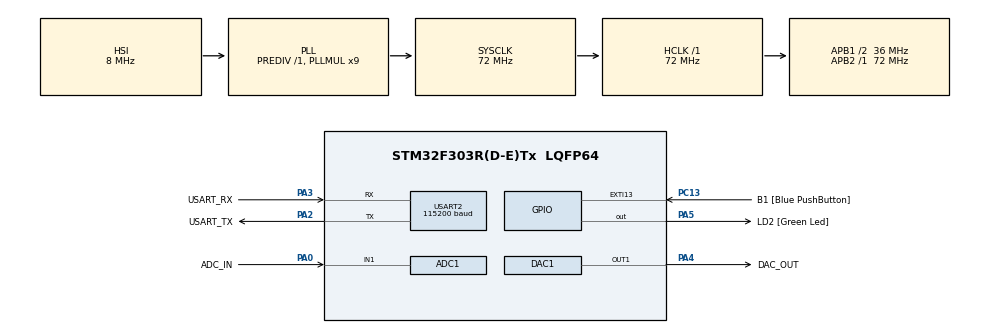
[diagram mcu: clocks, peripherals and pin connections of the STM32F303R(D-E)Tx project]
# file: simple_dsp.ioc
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ADC1.Channel-0\#ChannelRegularConversion=ADC_CHANNEL_1
ADC1.ClockPrescaler=ADC_CLOCK_SYNC_PCLK_DIV2
ADC1.ContinuousConvMode=DISABLE
ADC1.DMAContinuousRequests=ENABLE
ADC1.ExternalTrigConv=ADC_EXTERNALTRIGCONV_T6_TRGO
ADC1.NbrOfConversionFlag=1
ADC1.Offset-0\#ChannelRegularConversion=0
ADC1.OffsetNumber-0\#ChannelRegularConversion=ADC_OFFSET_NONE
ADC1.Rank-0\#ChannelRegularConversion=1
ADC1.SamplingTime-0\#ChannelRegularConversion=ADC_SAMPLETIME_181CYCLES_5
ADC1.master=1
DAC1.DAC_Trigger=DAC_TRIGGER_T6_TRGO
Dma.ADC1.1.Direction=DMA_PERIPH_TO_MEMORY
Dma.ADC1.1.Instance=DMA1_Channel1
Dma.ADC1.1.MemDataAlignment=DMA_MDATAALIGN_HALFWORD
Dma.ADC1.1.MemInc=DMA_MINC_ENABLE
Dma.ADC1.1.Mode=DMA_CIRCULAR
Dma.ADC1.1.PeriphDataAlignment=DMA_PDATAALIGN_HALFWORD
Dma.ADC1.1.PeriphInc=DMA_PINC_DISABLE
Dma.ADC1.1.Priority=DMA_PRIORITY_MEDIUM
Dma.DAC1_CH1.0.Direction=DMA_MEMORY_TO_PERIPH
Dma.DAC1_CH1.0.Instance=DMA1_Channel3
Dma.DAC1_CH1.0.MemDataAlignment=DMA_MDATAALIGN_HALFWORD
Dma.DAC1_CH1.0.MemInc=DMA_MINC_ENABLE
Dma.DAC1_CH1.0.Mode=DMA_CIRCULAR
Dma.DAC1_CH1.0.PeriphDataAlignment=DMA_PDATAALIGN_HALFWORD
Dma.DAC1_CH1.0.PeriphInc=DMA_PINC_DISABLE
Dma.DAC1_CH1.0.Priority=DMA_PRIORITY_MEDIUM
Dma.Request0=DAC1_CH1
Dma.Request1=ADC1
Dma.Request2=USART2_TX
Dma.USART2_TX.2.Direction=DMA_MEMORY_TO_PERIPH
Dma.USART2_TX.2.Instance=DMA1_Channel7
Dma.USART2_TX.2.MemDataAlignment=DMA_MDATAALIGN_BYTE
Dma.USART2_TX.2.MemInc=DMA_MINC_ENABLE
Dma.USART2_TX.2.Mode=DMA_NORMAL
Dma.USART2_TX.2.PeriphDataAlignment=DMA_PDATAALIGN_BYTE
Dma.USART2_TX.2.PeriphInc=DMA_PINC_DISABLE
Dma.USART2_TX.2.Priority=DMA_PRIORITY_LOW
Mcu.Family=STM32F3
Mcu.Name=STM32F303R(D-E)Tx
Mcu.Package=LQFP64
NVIC.DMA1_Channel1_IRQn=true\:0\:0\:false\:false\:false\:false\:false
NVIC.DMA1_Channel3_IRQn=true\:0\:0\:false\:false\:false\:false\:false
NVIC.DMA1_Channel7_IRQn=true\:0\:0\:false\:false\:true\:false\:true
NVIC.PriorityGroup=NVIC_PRIORITYGROUP_0
NVIC.USART2_IRQn=true\:0\:0\:false\:false\:false\:true\:false
PA0.GPIO_Label=ADC_IN
PA0.Mode=IN1-Single-Ended
PA0.Signal=ADC1_IN1
PA13.GPIO_Label=TMS
PA13.Mode=Serial_Wire
PA13.Signal=SYS_JTMS-SWDIO
PA14.GPIO_Label=TCK
PA14.Mode=Serial_Wire
PA14.Signal=SYS_JTCK-SWCLK
PA2.GPIO_Label=USART_TX
PA2.GPIO_Mode=GPIO_MODE_AF_PP
PA2.GPIO_PuPd=GPIO_NOPULL
PA2.GPIO_Speed=GPIO_SPEED_FREQ_LOW
PA2.Mode=Asynchronous
PA2.Signal=USART2_TX
PA3.GPIO_Label=USART_RX
PA3.GPIO_Mode=GPIO_MODE_AF_PP
PA3.GPIO_PuPd=GPIO_NOPULL
PA3.GPIO_Speed=GPIO_SPEED_FREQ_LOW
PA3.Mode=Asynchronous
PA3.Signal=USART2_RX
PA4.GPIO_Label=DAC_OUT
PA4.Signal=COMP_DAC11_group
PA5.GPIO_Label=LD2 [Green Led]
PA5.GPIO_Mode=GPIO_MODE_OUTPUT_PP
PA5.GPIO_PuPd=GPIO_NOPULL
PA5.GPIO_Speed=GPIO_SPEED_FREQ_HIGH
PA5.Signal=GPIO_Output
PB3.GPIO_Label=SWO
PB3.Signal=SYS_JTDO-TRACESWO
PC13.GPIO_Label=B1 [Blue PushButton]
PC13.GPIO_ModeDefaultEXTI=GPIO_MODE_IT_FALLING
PC13.Signal=GPXTI13
PC14-OSC32_IN.Mode=LSE-External-Oscillator
PC14-OSC32_IN.Signal=RCC_OSC32_IN
PC15-OSC32_OUT.Mode=LSE-External-Oscillator
PC15-OSC32_OUT.Signal=RCC_OSC32_OUT
PF0-OSC_IN.Mode=HSE-External-Clock-Source
PF0-OSC_IN.Signal=RCC_OSC_IN
PF1-OSC_OUT.Signal=RCC_OSC_OUT
ProjectManager.HeapSize=0x0
ProjectManager.StackSize=0x4000
ProjectManager.TargetToolchain=STM32CubeIDE
RCC.AHBFreq_Value=72000000
RCC.APB1CLKDivider=RCC_HCLK_DIV2
RCC.APB1Freq_Value=36000000
RCC.APB1TimFreq_Value=72000000
RCC.APB2Freq_Value=72000000
RCC.APB2TimFreq_Value=72000000
RCC.CortexFreq_Value=72000000
RCC.HCLKFreq_Value=72000000
RCC.HSE_VALUE=8000000
RCC.HSI_VALUE=8000000
RCC.PLLM=8
RCC.PLLMUL=RCC_PLL_MUL9
RCC.PLLN=336
RCC.PLLP=RCC_PLLP_DIV4
RCC.PLLQ=7
RCC.RCC_PLLsource_Clock_Source_FROM_HSE=RCC_HSE_PREDIV_DIV2
RCC.SYSCLKFreq_VALUE=72000000
RCC.SYSCLKSourceVirtual=RCC_SYSCLKSOURCE_PLLCLK
RCC.USBFreq_Value=72000000
SH.COMP_DAC11_group.0=DAC1_OUT1,DAC_OUT1
TIM6.Period=1499
TIM6.TIM_MasterOutputTrigger=TIM_TRGO_UPDATE
USART2.BaudRate=115200
USART2.DMADisableonRxErrorParam=ADVFEATURE_DMA_DISABLEONRXERROR
USART2.OverrunDisableParam=ADVFEATURE_OVERRUN_DISABLE
USART2.VirtualMode-Asynchronous=VM_ASYNC
VP_TIM6_VS_ClockSourceINT.Mode=Enable_Timer
board=NUCLEO-F303RE

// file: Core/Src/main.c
/* USER CODE BEGIN Header */
/**
 ******************************************************************************
 * @file           : main.c
 * @brief          : Main program body
 ******************************************************************************
 * @attention
 *
 * <h2><center>&copy; Copyright (c) 2019 STMicroelectronics.
 * All rights reserved.</center></h2>
 *
 * This software component is licensed by ST under BSD 3-Clause license,
 * the "License"; You may not use this file except in compliance with the
 * License. You may obtain a copy of the License at:
 *                        opensource.org/licenses/BSD-3-Clause
 *
 ******************************************************************************
 */
/* USER CODE END Header */

#include "main.h"

/* USER CODE BEGIN Includes */

#include "arm_math.h"
#include "../../Modules/DSP/dsp.h"
#include "../../Modules/Memory/static_allocator.h"
#include "../../Modules/Menu/menu.h"

#include "../../Modules/DSP/filter_tests.h"

/* USER CODE END Includes */

void SystemClock_Config(void);
static void MX_GPIO_Init(void);
static void MX_DAC1_Init(void);
static void MX_USART2_UART_Init(void);
static void MX_DMA_Init(void);
static void MX_ADC1_Init(void);
static void MX_TIM6_Init(void);

/* USER CODE BEGIN 0 */

/**
 * Initializes all drivers and modules
 */
void main_Init(void) {
  stalloc_Init();
  dsp_Init();
  menu_Init();

  stalloc_Disable();
}

//TODO add const to function's parameters
//TODO add assert to function's parameters

/* USER CODE END 0 */

int main(void)
{

  /* MCU Configuration--------------------------------------------------------*/

  /* Reset of all peripherals, Initializes the Flash interface and the Systick. */
  HAL_Init();

  /* Configure the system clock */
  SystemClock_Config();

  /* Initialize all configured peripherals */
  MX_GPIO_Init();
  MX_DAC1_Init();
  MX_USART2_UART_Init();
  MX_DMA_Init();
  MX_ADC1_Init();
  MX_TIM6_Init();
  /* USER CODE BEGIN 2 */

  main_Init();

  /* USER CODE END 2 */

  /* Infinite loop */
  /* USER CODE BEGIN WHILE */
  while (1) {
    dsp_Process();

    /* USER CODE END WHILE */

  }
}

void SystemClock_Config(void)
{
  RCC_OscInitTypeDef RCC_OscInitStruct = {0};
  RCC_ClkInitTypeDef RCC_ClkInitStruct = {0};
  RCC_PeriphCLKInitTypeDef PeriphClkInit = {0};

  /** Initializes the CPU, AHB and APB busses clocks
  */
  RCC_OscInitStruct.OscillatorType = RCC_OSCILLATORTYPE_HSI;
  RCC_OscInitStruct.HSIState = RCC_HSI_ON;
  RCC_OscInitStruct.HSICalibrationValue = RCC_HSICALIBRATION_DEFAULT;
  RCC_OscInitStruct.PLL.PLLState = RCC_PLL_ON;
  RCC_OscInitStruct.PLL.PLLSource = RCC_PLLSOURCE_HSI;
  RCC_OscInitStruct.PLL.PLLMUL = RCC_PLL_MUL9;
  RCC_OscInitStruct.PLL.PREDIV = RCC_PREDIV_DIV1;
  if (HAL_RCC_OscConfig(&RCC_OscInitStruct) != HAL_OK)
  {
    Error_Handler();
  }
  /** Initializes the CPU, AHB and APB busses clocks
  */
  RCC_ClkInitStruct.ClockType = RCC_CLOCKTYPE_HCLK|RCC_CLOCKTYPE_SYSCLK
                              |RCC_CLOCKTYPE_PCLK1|RCC_CLOCKTYPE_PCLK2;
  RCC_ClkInitStruct.SYSCLKSource = RCC_SYSCLKSOURCE_PLLCLK;
  RCC_ClkInitStruct.AHBCLKDivider = RCC_SYSCLK_DIV1;
  RCC_ClkInitStruct.APB1CLKDivider = RCC_HCLK_DIV2;
  RCC_ClkInitStruct.APB2CLKDivider = RCC_HCLK_DIV1;

  if (HAL_RCC_ClockConfig(&RCC_ClkInitStruct, FLASH_LATENCY_2) != HAL_OK)
  {
    Error_Handler();
  }
  PeriphClkInit.PeriphClockSelection = RCC_PERIPHCLK_USART2;
  PeriphClkInit.Usart2ClockSelection = RCC_USART2CLKSOURCE_PCLK1;
  if (HAL_RCCEx_PeriphCLKConfig(&PeriphClkInit) != HAL_OK)
  {
    Error_Handler();
  }
}

static void MX_ADC1_Init(void)
{

  LL_ADC_InitTypeDef ADC_InitStruct = {0};
  LL_ADC_REG_InitTypeDef ADC_REG_InitStruct = {0};
  LL_ADC_CommonInitTypeDef ADC_CommonInitStruct = {0};

  LL_GPIO_InitTypeDef GPIO_InitStruct = {0};

  /* Peripheral clock enable */
  LL_AHB1_GRP1_EnableClock(LL_AHB1_GRP1_PERIPH_ADC12);

  LL_AHB1_GRP1_EnableClock(LL_AHB1_GRP1_PERIPH_GPIOA);
  /**ADC1 GPIO Configuration
  PA0   ------> ADC1_IN1
  */
  GPIO_InitStruct.Pin = ADC_IN_Pin;
  GPIO_InitStruct.Mode = LL_GPIO_MODE_ANALOG;
  GPIO_InitStruct.Pull = LL_GPIO_PULL_NO;
  LL_GPIO_Init(ADC_IN_GPIO_Port, &GPIO_InitStruct);

  /* ADC1 DMA Init */

  /* ADC1 Init */
  LL_DMA_SetDataTransferDirection(DMA1, LL_DMA_CHANNEL_1, LL_DMA_DIRECTION_PERIPH_TO_MEMORY);

  LL_DMA_SetChannelPriorityLevel(DMA1, LL_DMA_CHANNEL_1, LL_DMA_PRIORITY_MEDIUM);

  LL_DMA_SetMode(DMA1, LL_DMA_CHANNEL_1, LL_DMA_MODE_CIRCULAR);

  LL_DMA_SetPeriphIncMode(DMA1, LL_DMA_CHANNEL_1, LL_DMA_PERIPH_NOINCREMENT);

  LL_DMA_SetMemoryIncMode(DMA1, LL_DMA_CHANNEL_1, LL_DMA_MEMORY_INCREMENT);

  LL_DMA_SetPeriphSize(DMA1, LL_DMA_CHANNEL_1, LL_DMA_PDATAALIGN_HALFWORD);

  LL_DMA_SetMemorySize(DMA1, LL_DMA_CHANNEL_1, LL_DMA_MDATAALIGN_HALFWORD);

  /** Common config
  */
  ADC_InitStruct.Resolution = LL_ADC_RESOLUTION_12B;
  ADC_InitStruct.DataAlignment = LL_ADC_DATA_ALIGN_RIGHT;
  ADC_InitStruct.LowPowerMode = LL_ADC_LP_MODE_NONE;
  LL_ADC_Init(ADC1, &ADC_InitStruct);
  ADC_REG_InitStruct.TriggerSource = LL_ADC_REG_TRIG_EXT_TIM6_TRGO_ADC12;
  ADC_REG_InitStruct.SequencerLength = LL_ADC_REG_SEQ_SCAN_DISABLE;
  ADC_REG_InitStruct.SequencerDiscont = LL_ADC_REG_SEQ_DISCONT_DISABLE;
  ADC_REG_InitStruct.ContinuousMode = LL_ADC_REG_CONV_SINGLE;
  ADC_REG_InitStruct.DMATransfer = LL_ADC_REG_DMA_TRANSFER_UNLIMITED;
  ADC_REG_InitStruct.Overrun = LL_ADC_REG_OVR_DATA_OVERWRITTEN;
  LL_ADC_REG_Init(ADC1, &ADC_REG_InitStruct);
  LL_ADC_DisableIT_EOC(ADC1);
  LL_ADC_DisableIT_EOS(ADC1);
  ADC_CommonInitStruct.CommonClock = LL_ADC_CLOCK_SYNC_PCLK_DIV2;
  ADC_CommonInitStruct.Multimode = LL_ADC_MULTI_INDEPENDENT;
  LL_ADC_CommonInit(__LL_ADC_COMMON_INSTANCE(ADC1), &ADC_CommonInitStruct);
  LL_ADC_REG_SetTriggerEdge(ADC1, LL_ADC_REG_TRIG_EXT_RISING);
  /** Configure Regular Channel
  */
  LL_ADC_REG_SetSequencerRanks(ADC1, LL_ADC_REG_RANK_1, LL_ADC_CHANNEL_1);
  LL_ADC_SetChannelSamplingTime(ADC1, LL_ADC_CHANNEL_1, LL_ADC_SAMPLINGTIME_181CYCLES_5);
  LL_ADC_SetChannelSingleDiff(ADC1, LL_ADC_CHANNEL_1, LL_ADC_SINGLE_ENDED);

}

static void MX_DAC1_Init(void)
{

  LL_DAC_InitTypeDef DAC_InitStruct = {0};

  LL_GPIO_InitTypeDef GPIO_InitStruct = {0};

  /* Peripheral clock enable */
  LL_APB1_GRP1_EnableClock(LL_APB1_GRP1_PERIPH_DAC1);

  LL_AHB1_GRP1_EnableClock(LL_AHB1_GRP1_PERIPH_GPIOA);
  /**DAC1 GPIO Configuration
  PA4   ------> DAC1_OUT1
  */
  GPIO_InitStruct.Pin = DAC_OUT_Pin;
  GPIO_InitStruct.Mode = LL_GPIO_MODE_ANALOG;
  GPIO_InitStruct.Pull = LL_GPIO_PULL_NO;
  LL_GPIO_Init(DAC_OUT_GPIO_Port, &GPIO_InitStruct);

  /* DAC1 DMA Init */

  /* DAC1_CH1 Init */
  LL_DMA_SetDataTransferDirection(DMA1, LL_DMA_CHANNEL_3, LL_DMA_DIRECTION_MEMORY_TO_PERIPH);

  LL_DMA_SetChannelPriorityLevel(DMA1, LL_DMA_CHANNEL_3, LL_DMA_PRIORITY_MEDIUM);

  LL_DMA_SetMode(DMA1, LL_DMA_CHANNEL_3, LL_DMA_MODE_CIRCULAR);

  LL_DMA_SetPeriphIncMode(DMA1, LL_DMA_CHANNEL_3, LL_DMA_PERIPH_NOINCREMENT);

  LL_DMA_SetMemoryIncMode(DMA1, LL_DMA_CHANNEL_3, LL_DMA_MEMORY_INCREMENT);

  LL_DMA_SetPeriphSize(DMA1, LL_DMA_CHANNEL_3, LL_DMA_PDATAALIGN_HALFWORD);

  LL_DMA_SetMemorySize(DMA1, LL_DMA_CHANNEL_3, LL_DMA_MDATAALIGN_HALFWORD);

  LL_SYSCFG_SetRemapDMA_DAC(LL_SYSCFG_DAC1_CH1_RMP_DMA1_CH3);

  /** DAC channel OUT1 config
  */
  DAC_InitStruct.TriggerSource = LL_DAC_TRIG_EXT_TIM6_TRGO;
  DAC_InitStruct.WaveAutoGeneration = LL_DAC_WAVE_AUTO_GENERATION_NONE;
  DAC_InitStruct.OutputBuffer = LL_DAC_OUTPUT_BUFFER_ENABLE;
  LL_DAC_Init(DAC1, LL_DAC_CHANNEL_1, &DAC_InitStruct);
  LL_DAC_EnableTrigger(DAC1, LL_DAC_CHANNEL_1);

}

static void MX_TIM6_Init(void)
{

  LL_TIM_InitTypeDef TIM_InitStruct = {0};

  /* Peripheral clock enable */
  LL_APB1_GRP1_EnableClock(LL_APB1_GRP1_PERIPH_TIM6);

  TIM_InitStruct.Prescaler = 0;
  TIM_InitStruct.CounterMode = LL_TIM_COUNTERMODE_UP;
  TIM_InitStruct.Autoreload = 1499;
  LL_TIM_Init(TIM6, &TIM_InitStruct);
  LL_TIM_DisableARRPreload(TIM6);
  LL_TIM_SetTriggerOutput(TIM6, LL_TIM_TRGO_UPDATE);
  LL_TIM_DisableMasterSlaveMode(TIM6);

}

static void MX_USART2_UART_Init(void)
{

  LL_USART_InitTypeDef USART_InitStruct = {0};

  LL_GPIO_InitTypeDef GPIO_InitStruct = {0};

  /* Peripheral clock enable */
  LL_APB1_GRP1_EnableClock(LL_APB1_GRP1_PERIPH_USART2);

  LL_AHB1_GRP1_EnableClock(LL_AHB1_GRP1_PERIPH_GPIOA);
  /**USART2 GPIO Configuration
  PA2   ------> USART2_TX
  PA3   ------> USART2_RX
  */
  GPIO_InitStruct.Pin = USART_TX_Pin|USART_RX_Pin;
  GPIO_InitStruct.Mode = LL_GPIO_MODE_ALTERNATE;
  GPIO_InitStruct.Speed = LL_GPIO_SPEED_FREQ_LOW;
  GPIO_InitStruct.OutputType = LL_GPIO_OUTPUT_PUSHPULL;
  GPIO_InitStruct.Pull = LL_GPIO_PULL_NO;
  GPIO_InitStruct.Alternate = LL_GPIO_AF_7;
  LL_GPIO_Init(GPIOA, &GPIO_InitStruct);

  /* USART2 DMA Init */

  /* USART2_TX Init */
  LL_DMA_SetDataTransferDirection(DMA1, LL_DMA_CHANNEL_7, LL_DMA_DIRECTION_MEMORY_TO_PERIPH);

  LL_DMA_SetChannelPriorityLevel(DMA1, LL_DMA_CHANNEL_7, LL_DMA_PRIORITY_LOW);

  LL_DMA_SetMode(DMA1, LL_DMA_CHANNEL_7, LL_DMA_MODE_NORMAL);

  LL_DMA_SetPeriphIncMode(DMA1, LL_DMA_CHANNEL_7, LL_DMA_PERIPH_NOINCREMENT);

  LL_DMA_SetMemoryIncMode(DMA1, LL_DMA_CHANNEL_7, LL_DMA_MEMORY_INCREMENT);

  LL_DMA_SetPeriphSize(DMA1, LL_DMA_CHANNEL_7, LL_DMA_PDATAALIGN_BYTE);

  LL_DMA_SetMemorySize(DMA1, LL_DMA_CHANNEL_7, LL_DMA_MDATAALIGN_BYTE);

  /* USART2 interrupt Init */
  NVIC_SetPriority(USART2_IRQn, NVIC_EncodePriority(NVIC_GetPriorityGrouping(),0, 0));
  NVIC_EnableIRQ(USART2_IRQn);

  USART_InitStruct.BaudRate = 115200;
  USART_InitStruct.DataWidth = LL_USART_DATAWIDTH_8B;
  USART_InitStruct.StopBits = LL_USART_STOPBITS_1;
  USART_InitStruct.Parity = LL_USART_PARITY_NONE;
  USART_InitStruct.TransferDirection = LL_USART_DIRECTION_TX_RX;
  USART_InitStruct.HardwareFlowControl = LL_USART_HWCONTROL_NONE;
  USART_InitStruct.OverSampling = LL_USART_OVERSAMPLING_16;
  LL_USART_Init(USART2, &USART_InitStruct);
  LL_USART_DisableIT_CTS(USART2);
  LL_USART_DisableOverrunDetect(USART2);
  LL_USART_DisableDMADeactOnRxErr(USART2);
  LL_USART_ConfigAsyncMode(USART2);
  LL_USART_Enable(USART2);

}

static void MX_DMA_Init(void)
{

  /* Init with LL driver */
  /* DMA controller clock enable */
  LL_AHB1_GRP1_EnableClock(LL_AHB1_GRP1_PERIPH_DMA1);

  /* DMA interrupt init */
  /* DMA1_Channel1_IRQn interrupt configuration */
  NVIC_SetPriority(DMA1_Channel1_IRQn, NVIC_EncodePriority(NVIC_GetPriorityGrouping(),0, 0));
  NVIC_EnableIRQ(DMA1_Channel1_IRQn);
  /* DMA1_Channel3_IRQn interrupt configuration */
  NVIC_SetPriority(DMA1_Channel3_IRQn, NVIC_EncodePriority(NVIC_GetPriorityGrouping(),0, 0));
  NVIC_EnableIRQ(DMA1_Channel3_IRQn);
  /* DMA1_Channel7_IRQn interrupt configuration */
  NVIC_SetPriority(DMA1_Channel7_IRQn, NVIC_EncodePriority(NVIC_GetPriorityGrouping(),0, 0));
  NVIC_EnableIRQ(DMA1_Channel7_IRQn);

}

static void MX_GPIO_Init(void)
{
  LL_EXTI_InitTypeDef EXTI_InitStruct = {0};
  LL_GPIO_InitTypeDef GPIO_InitStruct = {0};

  /* GPIO Ports Clock Enable */
  LL_AHB1_GRP1_EnableClock(LL_AHB1_GRP1_PERIPH_GPIOC);
  LL_AHB1_GRP1_EnableClock(LL_AHB1_GRP1_PERIPH_GPIOF);
  LL_AHB1_GRP1_EnableClock(LL_AHB1_GRP1_PERIPH_GPIOA);
  LL_AHB1_GRP1_EnableClock(LL_AHB1_GRP1_PERIPH_GPIOB);

  /**/
  LL_GPIO_ResetOutputPin(LD2_GPIO_Port, LD2_Pin);

  /**/
  LL_SYSCFG_SetEXTISource(LL_SYSCFG_EXTI_PORTC, LL_SYSCFG_EXTI_LINE13);

  /**/
  LL_GPIO_SetPinPull(B1_GPIO_Port, B1_Pin, LL_GPIO_PULL_NO);

  /**/
  LL_GPIO_SetPinMode(B1_GPIO_Port, B1_Pin, LL_GPIO_MODE_INPUT);

  /**/
  EXTI_InitStruct.Line_0_31 = LL_EXTI_LINE_13;
  EXTI_InitStruct.Line_32_63 = LL_EXTI_LINE_NONE;
  EXTI_InitStruct.LineCommand = ENABLE;
  EXTI_InitStruct.Mode = LL_EXTI_MODE_IT;
  EXTI_InitStruct.Trigger = LL_EXTI_TRIGGER_FALLING;
  LL_EXTI_Init(&EXTI_InitStruct);

  /**/
  GPIO_InitStruct.Pin = LD2_Pin;
  GPIO_InitStruct.Mode = LL_GPIO_MODE_OUTPUT;
  GPIO_InitStruct.Speed = LL_GPIO_SPEED_FREQ_HIGH;
  GPIO_InitStruct.OutputType = LL_GPIO_OUTPUT_PUSHPULL;
  GPIO_InitStruct.Pull = LL_GPIO_PULL_NO;
  LL_GPIO_Init(LD2_GPIO_Port, &GPIO_InitStruct);

}

void Error_Handler(void)
{
}

/************************ (C) COPYRIGHT STMicroelectronics *****END OF FILE****/
